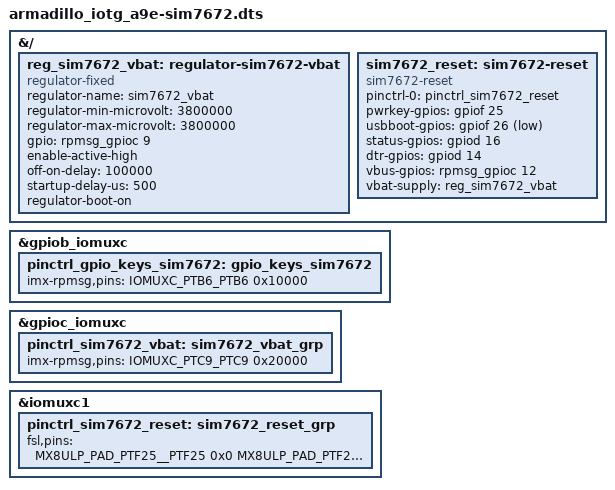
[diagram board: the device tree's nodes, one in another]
// SPDX-License-Identifier: (GPL-2.0 OR MIT)
/*
 * Copyright (C) 2024 Atmark Techno, Inc. All Rights Reserved.
 */

/dts-v1/;
/plugin/;

#include "imx8ulp-pinfunc-m33.h"
#include <dt-bindings/gpio/gpio.h>
#include <dt-bindings/input/input.h>
#include <dt-bindings/leds/common.h>

#include "imx8ulp-pinfunc.h"

&{/} {
	reg_sim7672_vbat: regulator-sim7672-vbat {
		compatible = "regulator-fixed";
		regulator-name = "sim7672_vbat";
		regulator-min-microvolt = <3800000>;
		regulator-max-microvolt = <3800000>;
		gpio = <&rpmsg_gpioc 9 GPIO_ACTIVE_HIGH>;
		enable-active-high;
		off-on-delay = <100000>;
		startup-delay-us = <500>;
		regulator-boot-on;
	};

	sim7672_reset: sim7672-reset {
		compatible = "sim7672-reset";
		pinctrl-names = "default";
		pinctrl-0 = <&pinctrl_sim7672_reset>;
		pwrkey-gpios = <&gpiof 25 GPIO_ACTIVE_HIGH>;
		usbboot-gpios = <&gpiof 26 GPIO_ACTIVE_LOW>;
		status-gpios = <&gpiod 16 GPIO_ACTIVE_HIGH>;
		dtr-gpios = <&gpiod 14 GPIO_ACTIVE_HIGH>;
		vbus-gpios = <&rpmsg_gpioc 12 GPIO_ACTIVE_HIGH>;
		vbat-supply = <&reg_sim7672_vbat>;
	};
#if 0 /* TODO: Fix how to use pins on Real Time Domain */
	gpio_keys_sim7672: gpio-keys-sim7672 {
		compatible = "gpio-keys";
		pinctrl-names = "default";
		pinctrl-0 = <&pinctrl_gpio_keys_sim7672>;

		sim7672-ri {
			label = "SIM7672-RI";
			gpios = <&rpmsg_gpiob 6 GPIO_ACTIVE_LOW>;
			linux,code = <KEY_PROG2>;
			gpio-key,wakeup;
		};
	};
#endif
};

#if 0 /* TODO: Fix how to use pins on Real Time Domain */
&uart2 {
	pinctrl-names = "default";
	pinctrl-0 = <&pinctrl_uart2>;
	status = "okay";
};
#endif

&gpiob_iomuxc {
	pinctrl_gpio_keys_sim7672: gpio_keys_sim7672 {
		imx-rpmsg,pins = <
			IOMUXC_PTB6_PTB6	0x10000 /* RI, IBE(1) */
		>;
	};
};

&gpioc_iomuxc {
	pinctrl_sim7672_vbat: sim7672_vbat_grp {
		imx-rpmsg,pins = <
			IOMUXC_PTC9_PTC9	0x20000 /* VBAT, OBE(1) */
		>;
	};
};

&iomuxc1 {
#if 0 /* TODO: Fix how to use pins on Real Time Domain */
	pinctrl_uart2: uart4grp {
		fsl,pins = <
			MX8ULP_PAD_PTB0__LPUART2_CTS_B	0x0
			MX8ULP_PAD_PTB2__LPUART2_TX	0x0
			MX8ULP_PAD_PTB3__LPUART2_RX	0x0
			MX8ULP_PAD_PTB1__LPUART2_RTS_B	0x0
		>;
	};
#endif

	pinctrl_sim7672_reset: sim7672_reset_grp {
		fsl,pins = <
			MX8ULP_PAD_PTF25__PTF25	0x0	/* PWRKEY */
			MX8ULP_PAD_PTF26__PTF26	0x0	/* USB_BOOT */
			MX8ULP_PAD_PTD16__PTD16	0x2	/* STATUS */
			MX8ULP_PAD_PTD14__PTD14 0x0     /* DTR */
		/*	MX8ULP_PAD_PTC12__PTC12	0x0 */	/* VBUS */
		>;
	};
};
